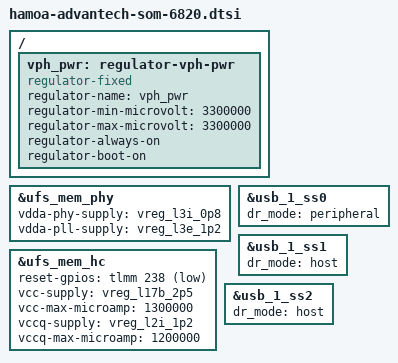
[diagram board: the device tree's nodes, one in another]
// SPDX-License-Identifier: BSD-3-Clause
/*
 * Copyright (c) Qualcomm Technologies, Inc. and/or its subsidiaries.
 *
 * SoM: https://advdownload.advantech.com.cn/productfile/PIS/SOM-6820/file/SOM-6820_DS(052925)20250529110758.pdf
 */

#include "hamoa-iot-som.dtsi"

/ {
	vph_pwr: regulator-vph-pwr {
		compatible = "regulator-fixed";

		regulator-name = "vph_pwr";
		regulator-min-microvolt = <3300000>;
		regulator-max-microvolt = <3300000>;

		regulator-always-on;
		regulator-boot-on;
	};
};

&ufs_mem_phy {
	vdda-phy-supply = <&vreg_l3i_0p8>;
	vdda-pll-supply = <&vreg_l3e_1p2>;

	status = "okay";
};

&ufs_mem_hc {
	reset-gpios = <&tlmm 238 GPIO_ACTIVE_LOW>;

	vcc-supply = <&vreg_l17b_2p5>;
	vcc-max-microamp = <1300000>;
	vccq-supply = <&vreg_l2i_1p2>;
	vccq-max-microamp = <1200000>;

	status = "okay";
};

&usb_1_ss0 {
	/delete-property/ usb-role-switch;
	dr_mode = "peripheral";
};

&usb_1_ss1 {
	/delete-property/ usb-role-switch;
	dr_mode = "host";
};

&usb_1_ss2 {
	/delete-property/ usb-role-switch;
	dr_mode = "host";
};
